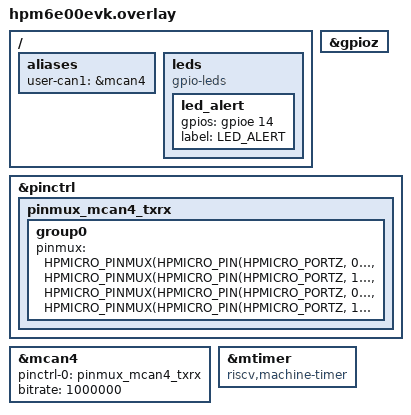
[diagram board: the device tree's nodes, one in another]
#include <dt-bindings/gpio/gpio.h>

/ {
	aliases {
		user-can1 = &mcan4;
	};
	leds {
		compatible = "gpio-leds";
		led_alert: led_alert {
			gpios = <&gpioe 14 (GPIO_ACTIVE_HIGH | GPIO_PULL_DOWN)>;
			label = "LED_ALERT";
		};
	};
};

&gpioz {
	status = "okay";
};

&pinctrl {
	pinmux_mcan4_txrx: pinmux_mcan4_txrx {
		group0 {
			pinmux = <HPMICRO_PINMUX(HPMICRO_PIN(HPMICRO_PORTZ, 0), IOC_TYPE_IOC , 0, 7)>,
				 	 <HPMICRO_PINMUX(HPMICRO_PIN(HPMICRO_PORTZ, 1), IOC_TYPE_IOC , 0, 7)>,
					 <HPMICRO_PINMUX(HPMICRO_PIN(HPMICRO_PORTZ, 0), IOC_TYPE_BIOC, 0, 3)>,
				 	 <HPMICRO_PINMUX(HPMICRO_PIN(HPMICRO_PORTZ, 1), IOC_TYPE_BIOC, 0, 3)>;
		};
	};
};

&mcan4 {
	status = "okay";
	pinctrl-0 = <&pinmux_mcan4_txrx>;
	pinctrl-names = "default";
	bitrate = <1000000>;
};

&mtimer {
	compatible = "riscv,machine-timer", "andestech,machine-timer";
	reg-names = "mtime", "mtimecmp";
};
